# tviic2d6mddr register map
Vendor: Cypress Semiconductor; Series: tviic2d6mddr; File version: 1.0
CPU: CM7 r0p1, little endian, MPU, FPU, VTOR, 3 interrupt priority bits
Registers are 32-bit, read-write, reset 0x0 unless marked. A register's access mark holds for its fields unless they carry their own. Offsets are from the block's base; [hi:lo] are bit positions; lines under a group give offsets from that group; {n}, {i} and the like mark numbered series; 'fields as' and 'values as' point back to an identical list.

## VIDEOSS0 (part 9 of 18) — Video and Graphics Subsystem IP
Base 0x40A00000
0x80000 VIDEOIO group — Video I/O Core
  0x00 SUBIO group — Sub Interface
    0x10000 COMPENG group — Composition Engine
      0x6400 FETCHDECODE0 group — FetchDecode #0 (Display)
        0x60 READADDRESS0 ro — Ring buffer synchronization for layer 0.
          [31:0] READADDRESS0 — Last burst address that was read from the layer's source buffer.
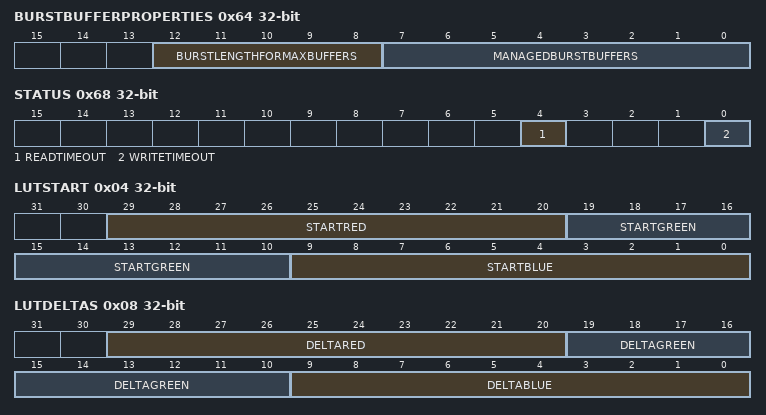
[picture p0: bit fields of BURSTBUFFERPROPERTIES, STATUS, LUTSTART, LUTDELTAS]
        0x64 BURSTBUFFERPROPERTIES ro reset not defined
          [12:8] BURSTLENGTHFORMAXBUFFERS — Maximum Burst Length that can be used when ManagedBurstBuffers burst buffers are used.
          [7:0] MANAGEDBURSTBUFFERS — Maximum number of burst buffers that can be administrated in the AXI interface.
        0x68 STATUS — Status information.
          [4] READTIMEOUT — Timeout detected when reading from the palette entries or shadow token trigger enables in FetchLayer derivate. Write 1 to clear.
          [0] WRITETIMEOUT — Timeout detected when writing to the palette entries or shadow token trigger enables in FetchLayer derivate. Write 1 to clear.
      0x6800 GAMMACOR4 group — Video Processing Block #0 GammaCor (Capture)
        0x00 STATICCONTROL reset 0xE — Static control settings.
          [3] REDWRITEENABLE — Write enable for the red color sampling point entries.
          [2] GREENWRITEENABLE — Write enable for the green color sampling point entries.
          [1] BLUEWRITEENABLE — Write enable for the blue color sampling point entries.
          [0] SHDEN — Enables shadowing of all RWS type registers (0=write_through, 1=shadowed).
        0x04 LUTSTART wo — Start values for look-up table programming.
          [29:20] STARTRED — Start value for red or luma (Y) channel. (format is unsigned integer)
          [19:10] STARTGREEN — Start value for green or chroma (U) channel. (format is unsigned integer)
          [9:0] STARTBLUE — Start value for blue or chroma (V) channel. (format is unsigned integer)
        0x08 LUTDELTAS wo reset not defined — Delta values for look-up table programming.
          [29:20] DELTARED — Delta value for red or luma (Y) channel. (format is signed integer)
          [19:10] DELTAGREEN — Delta value for green or chroma (U) channel. (format is signed integer)
          [9:0] DELTABLUE — Delta value for blue or chroma (V) channel. (format is signed integer)
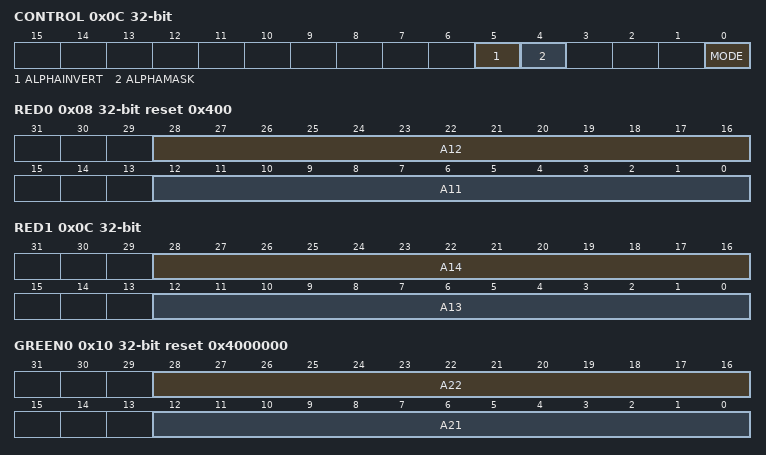
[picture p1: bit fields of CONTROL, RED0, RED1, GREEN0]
        0x0C CONTROL — Dynamic control settings.
          [5] ALPHAINVERT — Value 1 inverts the effect of the alpha mask mode when enabled (pixels with alpha value greater or equal 0.5 are by-passed).
          [4] ALPHAMASK — Value 1 enables the alpha mask mode. In this mode all pixels with an alpha value smaller than 0.5 are by-passed unchanged.
          [0] MODE — Operation mode for gamma correction unit
            0=NEUTRAL (Module in neutral mode, input data is bypassed to the output.); 1=GAMMACOR (Module in gamma correction mode.)
      0x6C00 MATRIX4 group — Video Processing Block #0 Matrix (Capture)
        0x00 STATICCONTROL — Color Matrix static control register
          [0] SHDEN — Enables shadowing of all RWS type registers (0=write_through, 1=shadowed).
        0x04 CONTROL — Color Matrix control register
          [5] ALPHAINVERT — Value 1 inverts the effect of the alpha mask mode when enabled (pixels with alpha value greater or equal 0.5 are by-passed).
          [4] ALPHAMASK — Value 1 enables the alpha mask mode. In this mode all pixels with an alpha value smaller than 0.5 are by-passed unchanged.
          [1:0] MODE — Operation mode for color matrix
            0=NEUTRAL (Module in neutral mode, input data is bypassed); 1=MATRIX (Module in matrix mode, input data is multiplied with matrix values); 2=PREMUL (Module in alpha pre-multiplication mode, input color is multiplied with input alpha); 3=RSVD (N/A)
        0x08 RED0 reset 0x400 — Matrix values for calculation of the red output value.
          [28:16] A12 — Value for green input. (format is signed fix-point 3.10)
          [12:0] A11 — Value for red input. (format is signed fix-point 3.10)
        0x0C RED1 — Matrix values for calculation of the red output value.
          [28:16] A14 — Value for alpha input. (format is signed fix-point 3.10)
          [12:0] A13 — Value for blue input. (format is signed fix-point 3.10)
        0x10 GREEN0 reset 0x4000000 — Matrix values for calculation of the green output value.
          [28:16] A22 — Value for green input. (format is signed fix-point 3.10)
          [12:0] A21 — Value for red input. (format is signed fix-point 3.10)
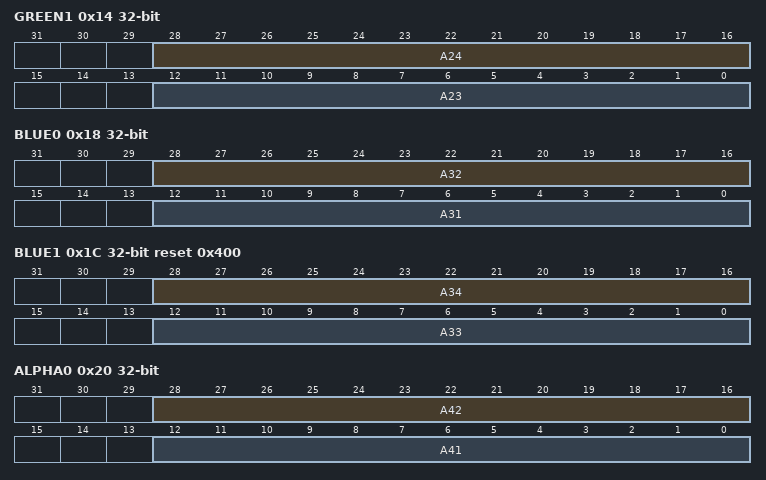
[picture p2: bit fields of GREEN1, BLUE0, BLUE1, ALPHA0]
        0x14 GREEN1 — Matrix values for calculation of the green output value.
          [28:16] A24 — Value for alpha input. (format is signed fix-point 3.10)
          [12:0] A23 — Value for blue input. (format is signed fix-point 3.10)
        0x18 BLUE0 — Matrix values for calculation of the blue output value.
          [28:16] A32 — Value for green input. (format is signed fix-point 3.10)
          [12:0] A31 — Value for red input. (format is signed fix-point 3.10)
        0x1C BLUE1 reset 0x400 — Matrix values for calculation of the blue output value.
          [28:16] A34 — Value for alpha input. (format is signed fix-point 3.10)
          [12:0] A33 — Value for blue input. (format is signed fix-point 3.10)
        0x20 ALPHA0 — Matrix values for calculation of the alpha output value.
          [28:16] A42 — Value for green input. (format is signed fix-point 3.10)
          [12:0] A41 — Value for red input. (format is signed fix-point 3.10)
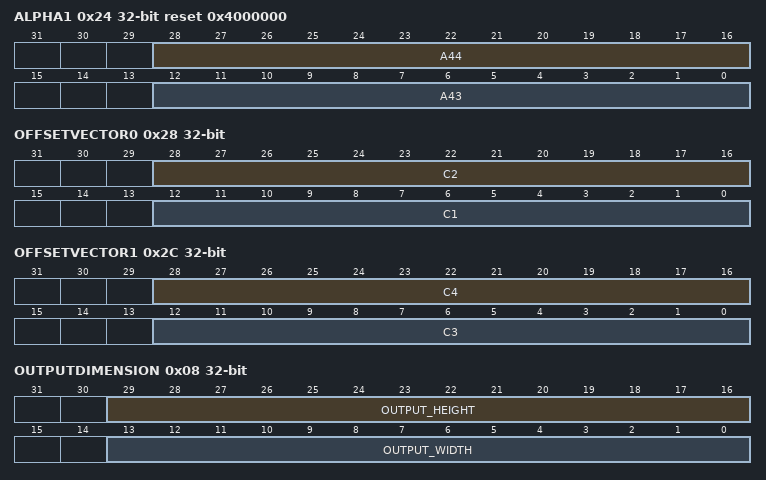
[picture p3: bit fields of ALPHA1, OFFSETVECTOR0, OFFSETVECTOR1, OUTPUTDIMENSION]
        0x24 ALPHA1 reset 0x4000000 — Matrix values for calculation of the alpha output value.
          [28:16] A44 — Value for alpha input. (format is signed fix-point 3.10)
          [12:0] A43 — Value for blue input. (format is signed fix-point 3.10)
        0x28 OFFSETVECTOR0 — Offset vectors for red and green output.
          [28:16] C2 — Green output offset. (format is signed integer)
          [12:0] C1 — Red output offset. (format is signed integer)
        0x2C OFFSETVECTOR1 — Offset vectors for blue and alpha output.
          [28:16] C4 — Alpha output offset. Note that the 8-bit alpha input is up-scaled to 10-bit, before the matrix and this offset is applied, and down-scaled to 8-bit for output afterwards. (format is signed integer)
          [12:0] C3 — Blue output offset. (format is signed integer)
      0x7000 GPSCALER4 group — GPscaler #4 (Capture)
        0x00 STATICCONTROL — Static control settings that must typically be setup once only.
          [0] SHDEN — If ShdEn==1 shadow registers are loaded when indicated by hardware signal ( a command signal in the data stream at frame start ). If ShdEn==0 shadow registers are loaded each frame start. (format is unsigned integer)
        0x04 CONTROL — Global operation control.
          [8] OPERATION_MODE — Selects the kind of operation to execute. (format is unsigned integer)
            0=SCALE (Scaler is active with the corresponding settings from scaler registers; filter registers are ignored.); 1=FIR (FIR-Filter is active with the corresponding settings from filter registers; scaler registers are ignored.)
          [3:0] MODE — Controls the sequence of horizontal and vertical operation for all operation modes. (format is unsigned integer)
            0=NEUTRAL (Neutral mode. Pixels are by-passed unchanged, all other settings are ignored.); 14=ACTIVE_AUTO (Automatic mode. Behaves like ACTIVE_VER_FIRST when operation_mode=SCALE and scale_mode_h=UPSCALE, like ACTIVE_HOR_FIRST otherwise.); 12=ACTIVE_HOR_FIRST (Horizontal is done before vertical operation.); 13=ACTIVE_VER_FIRST (Vertical is done before horizontal operation.); 8=ACTIVE_HOR_ONLY (Only horizontal operation is done.); 5=ACTIVE_VER_ONLY (Only vertical operation is done.)
        0x08 OUTPUTDIMENSION — Dimensions of the output frame or fame slice. This values are required for both FIR filter and scaler, since their output may have other dimension than input. The dimension of scaler's output is defined by the scale factor. The dimension of FIR filter's output depends on the tiling at the begin and the end of the slice.
          [29:16] OUTPUT_HEIGHT — Number of output lines per input frame or slice. This number is equal to the height of the output frame minus one. (format is unsigned integer)
          [13:0] OUTPUT_WIDTH — Number of output pixel per input line. This number is equal to the width of the output frame minus one. (format is unsigned integer)
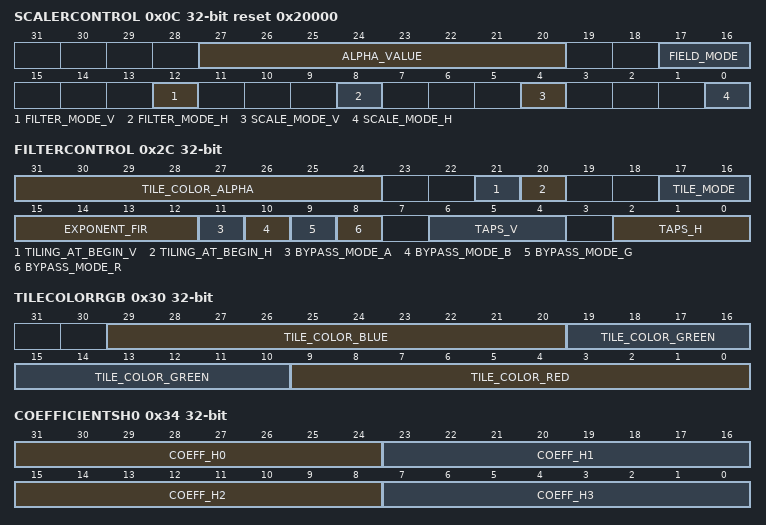
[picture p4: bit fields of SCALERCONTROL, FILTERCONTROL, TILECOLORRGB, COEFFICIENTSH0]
        0x0C SCALERCONTROL reset 0x20000 — Scaler operation control.
          [27:20] ALPHA_VALUE — When 'mode' field is not 'NEUTRAL', then input alpha values are ignore and output alpha set to this constant value for all pixels. This restriction applies to GPScalerL derivative only. (format is unsigned integer)
          [17:16] FIELD_MODE — Controls generation of output field polarity for vertical scaling. (format is unsigned integer)
            0=ALWAYS0 (Constant 0 indicates frame or top field.); 1=ALWAYS1 (Constant 1 indicates bottom field.); 2=INPUT (Output field polarity is taken from input field polarity.); 3=TOGGLE (Output field polarity toggles, starting with 0 after reset.)
          [12] FILTER_MODE_V — Selects sampling algorithm for vertical scaling. (format is unsigned integer)
            0=NEAREST (Nearest filter (point-sampling)); 1=LINEAR (Box filter (linear))
          [8] FILTER_MODE_H — Selects sampling algorithm for horizontal scaling. (format is unsigned integer)
            values as FILTER_MODE_V
          [4] SCALE_MODE_V — Scale mode for vertical scaling. (format is unsigned integer)
            0=DOWNSCALE (Down-scaling (output height less or equal input height).); 1=UPSCALE (Up-scaling (output height greater or equal input height))
          [0] SCALE_MODE_H — Scale mode for horizontal scaling. (format is unsigned integer)
            0=DOWNSCALE (Down-scaling (output width is less or equal input width).); 1=UPSCALE (Up-scaling (output width greater or equal input width))
        0x10 SCALERSETUPH0 reset 0x80000 — Phase interpolator setup.
          [19:0] SCALE_FACTOR_H — Scale factor has to be greater than 0.0 and less than or equal to 1.0. If scale_mode is UPSCALE then the inverse scale factor has to be programmed. (format is unsigned fix-point 1.19)
        0x14 SCALERSETUPH1 — Phase interpolator setup.
          [20:0] PHASE_OFFSET_H — Phase offset has to be larger than -2 and smaller than +2. Depending on scale_mode this value is relative to input (UPSCALE) or output pixel (DOWNSCALE). A negative value shifts the image to the right, a positive one to the left. (format is signed fix-point 2.19)
        0x18 SCALERSETUPV0 reset 0x80000 — Phase interpolator setup.
          [19:0] SCALE_FACTOR_V — Scale factor is greater than 0.0 and less than or equal to 1.0. If scale_mode is UPSCALE then the inverse scale factor have to be programmed. (format is unsigned fix-point 1.19)
        0x1C SCALERSETUPV1 — Phase interpolator setup, selected if input and output field polarity is 0.
          [20:0] PHASE_OFFSET_V — Phase offset has to be larger than -2 and smaller than +2. Depending on scale_mode this value is relative to input (UPSCALE) or output pixel (DOWNSCALE). A negative value shifts the image to the bottom, a positive one to the top. (format is signed fix-point 2.19)
        0x20 SCALERSETUPV2 — Phase interpolator setup, selected if input field polarity is 1 and output field polarity is 0.
          [20:0] PHASE_OFFSET_V1 — Phase offset has to be larger than -2 and smaller than +2. Depending on scale_mode this value is relative to input (UPSCALE) or output pixel (DOWNSCALE). A negative value shifts the image to the bottom, a positive one to the top. (format is signed fix-point 2.19)
        0x24 SCALERSETUPV3 — Phase interpolator setup, selected if input field polarity is 0 and output field polarity is 1.
          [20:0] PHASE_OFFSET_V2 — Phase offset has to be larger than -2 and smaller than +2. Depending on scale_mode this value is relative to input (UPSCALE) or output pixel (DOWNSCALE). A negative value shifts the image to the bottom, a positive one to the top. (format is signed fix-point 2.19)
        0x28 SCALERSETUPV4 — Phase interpolator setup, selected if input and output field polarity is 1.
          [20:0] PHASE_OFFSET_V3 — Phase offset has to be larger than -2 and smaller than +2. Depending on scale_mode this value is relative to input (UPSCALE) or output pixel (DOWNSCALE). A negative value shifts the image to the bottom, a positive one to the top. (format is signed fix-point 2.19)
        0x2C FILTERCONTROL — Filter operation control.
          [31:24] TILE_COLOR_ALPHA — Sets the alpha value for pixels outside of the slice. (format is unsigned integer)
          [21] TILING_AT_BEGIN_V — If set to true, this bit enables tiling at the begin of the slice for vertical direction. Tiling at the end occurs automatically by setting the corresponding output size. (format is unsigned integer)
          [20] TILING_AT_BEGIN_H — If set to true, this bit enables tiling at the begin of the slice for horizontal direction. Tiling at the end occurs automatically by setting the corresponding output size. (format is unsigned integer)
          [17:16] TILE_MODE — Selects the tile mode for pixels outside the source frame. In order to enable tiling tiling_at_begin_h or tiling_at_begin_v and the corresponding output frame dimension have to be set. (format is unsigned integer)
            0=TILE_FILL_ZERO (Use zero value.); 1=TILE_FILL_CONSTANT (Use constant color value from the field tile_color.); 2=TILE_PAD (Use closest pixel from source frame.); 3=TILE_PAD_ZERO (Use closest pixel from source buffer but zero for alpha component.)
          [15:12] EXPONENT_FIR — FIR product sum is divided by 2**FIR_exponent and rounded. (format is unsigned integer)
          [11] BYPASS_MODE_A — Bypass configuration for alpha components of every pixel. (format is unsigned integer)
            0=NEUTRAL (Alpha is filtered.); 1=ACTIVE (Alpha is not filtered, but is written to the line buffer.)
          [10] BYPASS_MODE_B — Bypass configuration for blue color components of every pixel. (format is unsigned integer)
            0=NEUTRAL (Blue color is filtered.); 1=ACTIVE (Blue color is not filtered, but is written to the line buffer.)
          [9] BYPASS_MODE_G — Bypass configuration for green color components of every pixel. (format is unsigned integer)
            0=NEUTRAL (Green color is filtered.); 1=ACTIVE (Green color is not filtered, but is written to the line buffer.)
          [8] BYPASS_MODE_R — Bypass configuration for red color components of every pixel. (format is unsigned integer)
            0=NEUTRAL (Red color is filtered.); 1=ACTIVE (Red color is not filtered, but is written to the line buffer.)
          [6:4] TAPS_V — Defines the vertical size of the FIR filter between 1 and 15 with increment of 2. Only odd filter width is supported. To program this field following formula has to be used: (filter height - 1)/2 (format is unsigned integer)
          [2:0] TAPS_H — Defines the horizontal size of the FIR filter between 1 and 15 with increment of 2. Only odd filter width is supported. To program this field following formula has to be used: (filter width - 1)/2 (format is unsigned integer)
        0x30 TILECOLORRGB — Color for outside of the slice.
          [29:20] TILE_COLOR_BLUE — Sets the blue color value for pixels outside of the slice. (format is unsigned integer)
          [19:10] TILE_COLOR_GREEN — Sets the green color value for pixels outside of the slice. (format is unsigned integer)
          [9:0] TILE_COLOR_RED — Sets the red color value for pixels outside of the slice. (format is unsigned integer)
        0x34 COEFFICIENTSH0 — Horizontal coefficients for filter_mode FIR.
          [31-8n:24-8n] COEFF_H{n} (n=0..3) — Horizontal coefficient {n}. (format is signed integer)
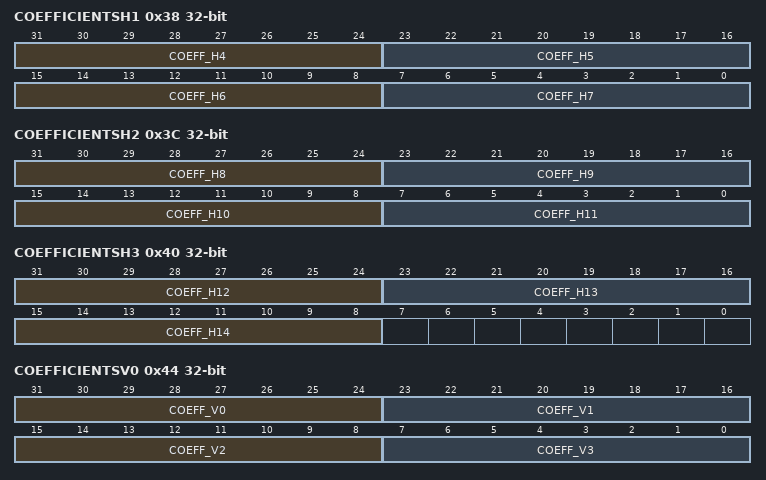
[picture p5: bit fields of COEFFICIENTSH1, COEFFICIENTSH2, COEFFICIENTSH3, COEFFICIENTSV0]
        0x38 COEFFICIENTSH1 — Horizontal coefficients for filter_mode FIR.
          [63-8n:56-8n] COEFF_H{n} (n=4..7) — Horizontal coefficient {n}. (format is signed integer)
        0x3C COEFFICIENTSH2 — Horizontal coefficients for filter_mode FIR.
          [95-8n:88-8n] COEFF_H{n} (n=8..11) — Horizontal coefficient {n}. (format is signed integer)
        0x40 COEFFICIENTSH3 — Horizontal coefficients for filter_mode FIR.
          [31:24] COEFF_H12 — Horizontal coefficient 12. (format is signed integer)
          [23:16] COEFF_H13 — Horizontal coefficient 13. (format is signed integer)
          [15:8] COEFF_H14 — Horizontal coefficient 14. The rightmost coefficient regardless of the filter width. In contrast to the coeff_h0 this coefficient has to be always programmed. (format is signed integer)
        0x44 COEFFICIENTSV0 — Vertical coefficients for filter_mode FIR.
          [31-8n:24-8n] COEFF_V{n} (n=0..3) — Vertical coefficient {n}. (format is signed integer)
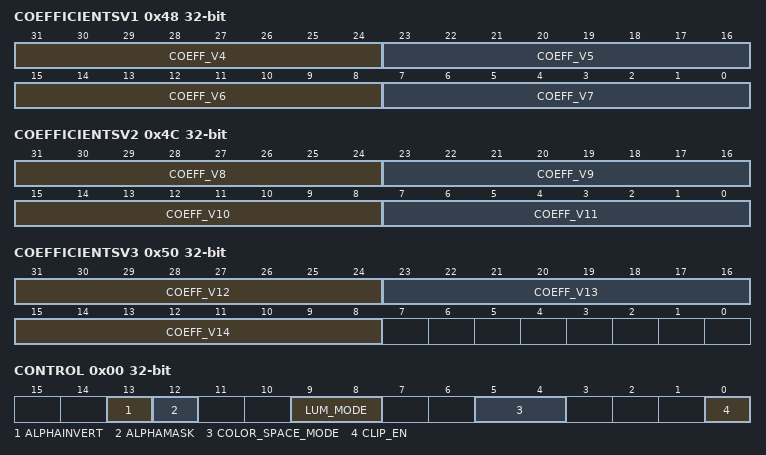
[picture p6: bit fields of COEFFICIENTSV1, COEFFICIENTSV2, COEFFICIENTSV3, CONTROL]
        0x48 COEFFICIENTSV1 — Vertical coefficients for filter_mode FIR.
          [63-8n:56-8n] COEFF_V{n} (n=4..7) — Vertical coefficient {n}. (format is signed integer)
        0x4C COEFFICIENTSV2 — Vertical coefficients for filter_mode FIR.
          [95-8n:88-8n] COEFF_V{n} (n=8..11) — Vertical coefficient {n}. (format is signed integer)
        0x50 COEFFICIENTSV3 — Vertical coefficients for filter_mode FIR.
          [31:24] COEFF_V12 — Vertical coefficient 12. (format is signed integer)
          [23:16] COEFF_V13 — Vertical coefficient 13. (format is signed integer)
          [15:8] COEFF_V14 — Vertical coefficient 14. The bottommost coefficient regardless of the filter height. In contrast to the coeff_v0 this coefficient has to be always programmed. (format is signed integer)
      0x7400 HISTOGRAM4 group — Video Processing Block #0 Histogram (Capture)
        0x00 CONTROL — Controls some settings concerning input components and alpha mask.
          [13] ALPHAINVERT — Value 1 inverts the effect of the alpha mask mode when enabled (pixels with alpha value smaller or equal 0.5 are affecting the histogram bins).
          [12] ALPHAMASK — Value 1 enables the alpha mask mode. In this mode only pixels with an alpha value larger than 0.5 are affecting the histogram bins.
          [9:8] LUM_MODE — If a histogram for luma or luminance is required, the conversion formula for luma (Y component according to BT.601) or luminance (Y component according to BT.709) can be selected here. Luma or luminance calculation should only be applied if RGB components in range [0..255] are delivered directly at histogram input or when YCrCb components are converted to RGB by the appropriate setting of register field color_space_mode. Luma or luminance counting is delivered in first (component0) histogram. (format is unsigned integer)
            0=NO_CONV (Component0 for first histogram is counted as it is.); 1=LUMA (Component0 for first histogram is replaced by luma, which is calculated from RGB input components according to BT.601.); 2=LUMINANCE (Component0 for first histogram is replaced by luminance, which is calculated from RGB input components according to BT.709.)
          [5:4] COLOR_SPACE_MODE — Assuming that YUV(YCrCb) color components according to BT.601 or BT.709 are provided at histogram input the appropriate conversion to RGB components in [0,255] range can be selected here. (format is unsigned integer)
            0=NO_CONV (No color space conversion of input components is applied.); 1=YUV2RGB_BT601 (YUV input components as described in BT.601 are converted to RGB in [0,255] range.); 2=YUV2RGB_BT709 (YUV input components as described in BT.709 are converted to RGB in [0,255] range.)
          [0] CLIP_EN — Switch for clip window. If enabled all pixels outside the clip window are not taken into account. (format is unsigned integer)
            0=DISABLE (Clip window is switched off.); 1=ENABLE (Clip window is switched on.)
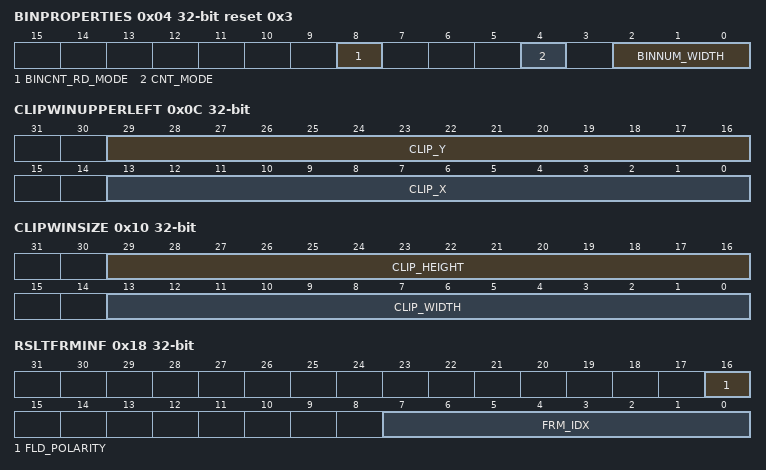
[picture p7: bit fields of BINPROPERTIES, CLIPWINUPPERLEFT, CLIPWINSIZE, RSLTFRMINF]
        0x04 BINPROPERTIES reset 0x3 — Configures the histogram bins.
          [8] BINCNT_RD_MODE — The field controls if the actual bin count or the sum of all bin counts up to actual bin count is provided in registers RsltComp0Bincnt, RsltComp1Bincnt and RsltComp2Bincnt. (format is unsigned integer)
            0=BINCNT (Actual bin cnt is provided.); 1=BINCNT_ACCU (Bin count sum is provided.)
          [4] CNT_MODE — Counter mode, which controls the way the bin values are accumulated. (format is unsigned integer)
            0=NEAREST (Counter of nearest bin is incremented.); 1=LINEAR (Counters of the 2 nearest bins are increased by one minus the distance to bin center (normalized between 0 and 1), it works only for first (component0) histogram, reading of component1/2 histogram results in undefined data.)
          [2:0] BINNUM_WIDTH — 2**binnum_width is the number of bins in a histogram. (format is unsigned integer)
            3=BINS_8 (There are 8 bins, addressable with 3bit.); 4=BINS_16 (There are 16 bins, addressable with 4bit.); 5=BINS_32 (There are 32 bins, addressable with 5bit.); 6=BINS_64 (There are 64 bins, addressable with 6bit.)
        0x08 BINCNTTHRESH — Bin counter threshold value.
          [28:0] BINCNT_THRESH — Bin counters below this threshold will be reported as 0. This threshold value will also affect the BINCNT_ACCU mode where 0 will be added for all bin counters below the threshold. (format is unsigned integer)
        0x0C CLIPWINUPPERLEFT — Coordinates of upper left corner of clip window.
          [29:16] CLIP_Y — Y coordinate of upper left corner of clip window. (format is unsigned integer)
          [13:0] CLIP_X — X coordinate of upper left corner of clip window. (format is unsigned integer)
        0x10 CLIPWINSIZE — Dimensions of clip window.
          [29:16] CLIP_HEIGHT — Height of clip window, given minus one. (format is unsigned integer)
          [13:0] CLIP_WIDTH — Width of clip window, given minus one. (format is unsigned integer)
        0x14 RSLTRDY ro — Measurement result status.
          [0] RSLT_RDY — A one indicates that measurement results (in registers Rslt...) are valid and can be read. (format is unsigned integer)
        0x18 RSLTFRMINF ro — Additional information on the measurement results.
          [16] FLD_POLARITY — Returns field polarity of the measured frame. This read value of this field is undefined in display stream context; use in storage, content or safety stream context only. (format is unsigned integer)
          [7:0] FRM_IDX — Each frame passing the histogram unit gets an index, which is the value of a wrapped around counter, which counts the frames independent from how the histogram unit is configured. The index of the frame of the ongoing readout can be read here. In display stream context, if the display operation ends (framegen is switched off and sequence complete occurs) this frame index is reset to 0. (format is unsigned integer)
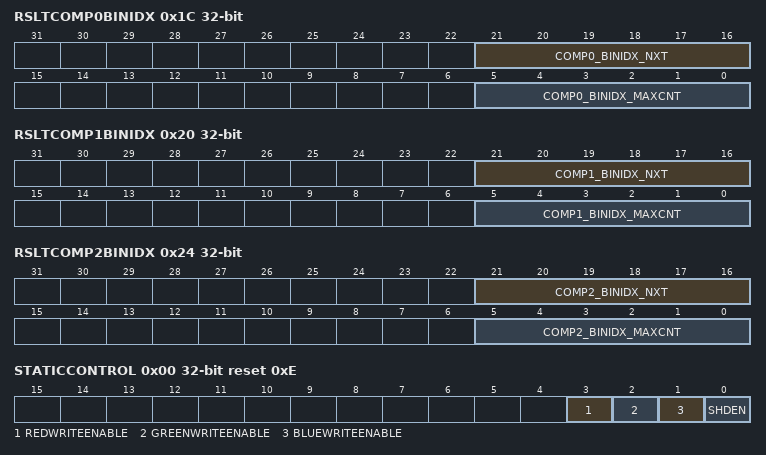
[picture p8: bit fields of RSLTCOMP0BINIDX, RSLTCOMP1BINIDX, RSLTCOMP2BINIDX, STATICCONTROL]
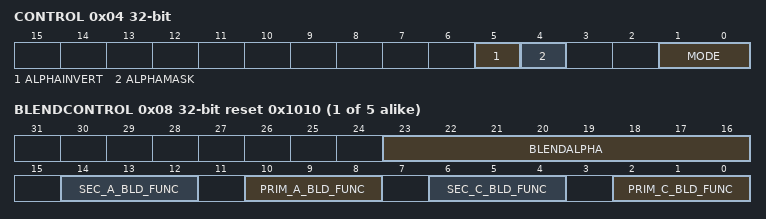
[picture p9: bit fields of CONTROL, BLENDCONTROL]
        0x1C RSLTCOMP0BINIDX ro — Results of frame measurement for component 0.
          [21:16] COMP0_BINIDX_NXT — Do not use this filed. The index of the bin, that will be next accessed by register RsltComp0Bincnt. In the case of RGB pixels, component0 means the red value, in the case of YUV pixels, component 0 means the Y value. If luma/luminance calculation is switched on by field lum_mode component0 is the calculated luma/luminance. (format is unsigned integer)
          [5:0] COMP0_BINIDX_MAXCNT — The index of the bin of the component 0 histogram, which contains the highest counter value, which were read until now for the ongoing readout. In the case of RGB pixels, component 0 means the red value, in the case of YUV pixels, component0 means the Y value. If luma/luminance calculation is switched on by field lum_mode component0 is the calculated luma/luminance. (format is unsigned integer)
        0x20 RSLTCOMP1BINIDX ro — Results of frame measurement for component 1.
          [21:16] COMP1_BINIDX_NXT — The index of the bin, that will be next accessed by register RsltComp1Bincnt. In the case of RGB pixels, component 1 means the green value. In the case of YUV pixels, component 1 means the Cb value. (format is unsigned integer)
          [5:0] COMP1_BINIDX_MAXCNT — The index of the bin of the component 1 histogram, which contains the highest counter value, which were read until now for the ongoing readout. In the case of RGB pixels, component 1 means the green value. In the case of YUV pixels, component 1 means the Cb value. (format is unsigned integer)
        0x24 RSLTCOMP2BINIDX ro — Results of frame measurement for component 2.
          [21:16] COMP2_BINIDX_NXT — The index of the bin, that will be next accessed by register RsltComp2Bincnt. In the case of RGB pixels, component 2 means the blue value. In the case of YUV pixels, component 2 means the Cr value. (format is unsigned integer)
          [5:0] COMP2_BINIDX_MAXCNT — The index of the bin of the component 2 histogram, which contains the highest counter value, which were read until now for the ongoing readout. In the case of RGB pixels, component 2 means the blue value. In the case of YUV pixels, component 2 means the Cr value. (format is unsigned integer)
        0x28 RSLTCOMP0SUM ro — Sum of all component 0 values.
          [31:0] COMP0_SUM — Sum of all component 0 values. In the case of RGB pixels, component 0 means the red value, in the case of YUV pixels, component 0 means the Y value. If luma/luminance calculation is switched on by field lum_mode, component 0 is the calculated luma/luminance. If the read value is 0xFFFFFFFF a counter overflow has occurred and the read value should not be used (this can only happen for frame dimensions beyond 2^12 * 2^12). (format is unsigned integer)
        0x2C RSLTCOMP1SUM ro — Sum of all component 1 values.
          [31:0] COMP1_SUM — Sum of all component 1 values. In the case of RGB pixels, component 1 means the green value. In the case of YUV pixels, component 1 means the Cb value. If the read value is 0xFFFFFFFF a counter overflow has occurred and the read value should not be used (this can only happen for frame dimensions beyond 2^12 * 2^12). (format is unsigned integer)
        0x30 RSLTCOMP2SUM ro — Sum of all component 2 values.
          [31:0] COMP2_SUM — Sum of all component 2 values. In the case of RGB pixels, component 2 means the blue value. In the case of YUV pixels, component 2 means the Cr value. If the read value is 0xFFFFFFFF a counter overflow has occurred and the read value should not be used (this can only happen for frame dimensions beyond 2^12 * 2^12). (format is unsigned integer)
        0x34 RSLTCOMP0BINCNT ro — Bin counters of component 0 histogram. This register do NOT support debugger access followed by software access (they clear on read)
          [28:0] COMP0_BINCNT — Counter of current bin number in component 0 histogram. In the case of RGB pixels, component 0 means the red value, in the case of YUV pixels, component 0 means the Y value. (format is unsigned integer)
        0x38 RSLTCOMP1BINCNT ro — Bin counters of component 1 histogram. This register do NOT support debugger access followed by software access (they clear on read)
          [28:0] COMP1_BINCNT — Counter of current bin number in component 1 histogram. In the case of RGB pixels, component 1 means the green value. In the case of YUV pixels, component 1 means the Cb value. (format is unsigned integer)
        0x3C RSLTCOMP2BINCNT ro — Bin counters of component 2 histogram. This register do NOT support debugger access followed by software access (they clear on read)
          [28:0] COMP2_BINCNT — Counter of current bin index in component 2 histogram. In the case of RGB pixels, component 2 means the blue value. In the case of YUV pixels, component 2 means the Cb value. (format is unsigned integer)
        0x40 FRMSTRTTRIG wo reset not defined — Triggers for loading shadow registers and starting measurement with next input frame.
          [0] MSRMNT_STRT_TRIG — Writing value 1 into this field initiates the measurement of the next frame. (format is unsigned integer)
      {0x7400+0x400*l} LAYERBLEND{l} group (l=1..5) — LayerBlend #{l} (Display, Alpha Plane {l})
        0x00 STATICCONTROL reset 0x14 — Static control settings.
          [4:3] SHDTOKSEL — Controls when a shadow load token is generated on the output port, which controls shadow load in subsequent processing units.
            0=PRIMARY (When a token was received on the primary input (background plane).); 1=SECONDARY (When a token was received on the secondary input (foreground plane).); 2=BOTH (When a token was received on any input.)
          [2:1] SHDLDSEL — Controls when shadow fields of this unit are loaded into the active configuration in case that ShdEn is enabled.
            0=PRIMARY (Load shadows with shadow load token on primary input (background plane).); 1=SECONDARY (Load shadows with shadow load token on secondary input (foreground plane).); 2=BOTH (Load shadows with shadow load token on any input.)
          [0] SHDEN — Enables shadowing of all RWS type fields of this unit (0 = write through, 1 = shadowed).
        0x04 CONTROL reset 0x1 — Common control settings.
          [25:22] SECODDROWODDCOLDIS — Disable bits for R/Y, G/U, B/V and A channels of secondary input when row and column index is odd. R/Y is MSBit, A is LSBit.
          [21:18] SECODDROWEVENCOLDIS — Disable bits for R/Y, G/U, B/V and A channels of secondary input when row index is odd and column index is even. R/Y is MSBit, A is LSBit.
          [17:14] SECEVENROWODDCOLDIS — Disable bits for R/Y, G/U, B/V and A channels of secondary input when row index is even and column index is odd. R/Y is MSBit, A is LSBit.
          [13:10] SECEVENROWEVENCOLDIS — Disable bits for R/Y, G/U, B/V and A channels of secondary input when row and column index is even. R/Y is MSBit, A is LSBit.
          [9] SECREPLICATEEN — Enables horizontal replication of pixels by factor 2 on secondary input port. Must be used for dual display mode when the secondary input frame has the resolution of one display (= half the resolution of the panel interface).
          [8] SECLOWPASSEN — Enables a horizontal low-pass filter for the secondary input port. Should be used for dual view and dual display mode when the secondary input frame has twice the resolution of one view (= full resolution of the panel interface). Every 2nd pixel only is sampled then.
          [6:4] ALPHAMASKMODE — AlphaMaskMode determines how the output alpha is generated when AlphaMaskEnable is set to ENABLE
            0=PRIM (Areas with primary input alpha > 128 will be mapped to 255 and the rest will have an alpha value of 0); 1=SEC (The area of the secondary input will get an alpha value of 255 and the rest will be 0); 2=PRIM_OR_SEC (Behaves as if the output of modes PRIM and SEC would be ORed together); 3=PRIM_AND_SEC (Behaves as if the output of modes PRIM and SEC would be ANDed together); 4=PRIM_INV (Behaves as if the output of mode PRIM would be inverted); 5=SEC_INV (Behaves as if the output of mode SEC would be inverted); 6=PRIM_OR_SEC_INV (Behaves as if the output of modes PRIM and SEC_INV would be ORed together); 7=PRIM_AND_SEC_INV (Behaves as if the output of modes PRIM and SEC_INV would be ANDed together)
          [2] ALPHAMASKENABLE — Enables Alpha Mask feature. This will limit possible output alpha values to 0 and 255. Generation of this alpha value will depend on the AlphaMaskMode field.
            0=DISABLE (AlphaMask feature disabled); 1=ENABLE (AlphaMask feature enabled)
          [0] MODE — Operation mode.
            0=NEUTRAL (Module is in neutral mode. Output is same as primary input.); 1=BLEND (Module is in blending mode.)
        0x08 BLENDCONTROL reset 0x1010 — Options for blend operations
          [23:16] BLENDALPHA — Constant alpha value, used for constant alpha blending
          [14:12] SEC_A_BLD_FUNC — Secondary (overlay) input alpha blending function
            0=ZERO (Aout = Ain * 0); 1=ONE (Aout = Ain * 1); 2=PRIM_ALPHA (Aout = Ain * ALPHA_prim); 3=ONE_MINUS_PRIM_ALPHA (Aout = Ain * (1 - ALPHA_prim)); 4=SEC_ALPHA (Aout = Ain * ALPHA_sec); 5=ONE_MINUS_SEC_ALPHA (Aout = Ain * (1 - ALPHA_sec)); 6=CONST_ALPHA (Aout = Ain * ALPHA_const); 7=ONE_MINUS_CONST_ALPHA (Aout = Ain * (1 - ALPHA_const))
          [10:8] PRIM_A_BLD_FUNC — Primary (background) input alpha blending function
            values as SEC_A_BLD_FUNC
          [6:4] SEC_C_BLD_FUNC — Secondary (overlay) input color blending function
            0=ZERO (Cout = Cin * 0); 1=ONE (Cout = Cin * 1); 2=PRIM_ALPHA (Cout = Cin * ALPHA_prim); 3=ONE_MINUS_PRIM_ALPHA (Cout = Cin * (1 - ALPHA_prim)); 4=SEC_ALPHA (Cout = Cin * ALPHA_sec); 5=ONE_MINUS_SEC_ALPHA (Cout = Cin * (1 - ALPHA_sec)); 6=CONST_ALPHA (Cout = Cin * ALPHA_const); 7=ONE_MINUS_CONST_ALPHA (Cout = Cin * (1 - ALPHA_const))
          [2:0] PRIM_C_BLD_FUNC — Primary (background) input color blending function
            values as SEC_C_BLD_FUNC
